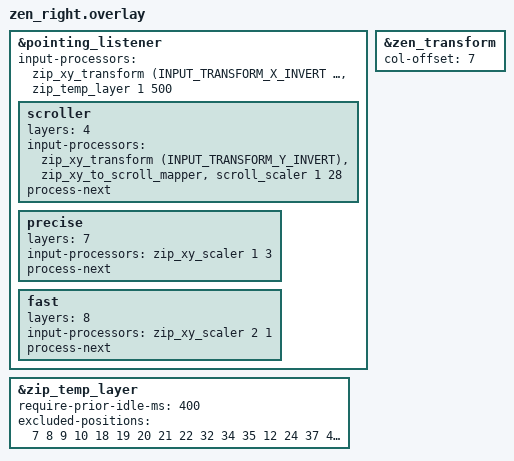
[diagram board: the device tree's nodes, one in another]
#include "zen.dtsi"
#include <input/processors.dtsi>
#include <dt-bindings/zmk/input_transform.h>

&pointing_listener {
    input-processors =
        <&zip_xy_transform (INPUT_TRANSFORM_X_INVERT | INPUT_TRANSFORM_Y_INVERT)>,
        <&zip_temp_layer 1 500>;

    scroller {
        layers = <4>;
        input-processors =
            <&zip_xy_transform (INPUT_TRANSFORM_Y_INVERT)>,
            <&zip_xy_to_scroll_mapper>,
            <&scroll_scaler 1 28>;
        process-next;
    };

    // Layer 7 (Precise): cursor at 1/3 speed while held.
    precise {
        layers = <7>;
        input-processors = <&zip_xy_scaler 1 3>;
        process-next;
    };

    // Layer 8 (Fast): cursor at 2x speed while held.
    fast {
        layers = <8>;
        input-processors = <&zip_xy_scaler 2 1>;
        process-next;
    };
};

// Auto mouse layer (layer 1) guards against brushing the trackball while typing:
// - require-prior-idle-ms: the layer only turns on once 400 ms have passed
//   since the last keystroke (the cursor itself still moves right away).
// - excluded-positions: pressing any other key turns the layer off at once.
//   Listed keys keep it on: mouse-layer keys (7-10 18-22 32 34 35) and the
//   modifiers used for Cmd/Shift/Option/Ctrl+click (12 24 37 40-43).
&zip_temp_layer {
    require-prior-idle-ms = <400>;
    excluded-positions = <7 8 9 10 18 19 20 21 22 32 34 35 12 24 37 40 41 42 43>;
};

&zen_transform {
    col-offset = <7>;
};
